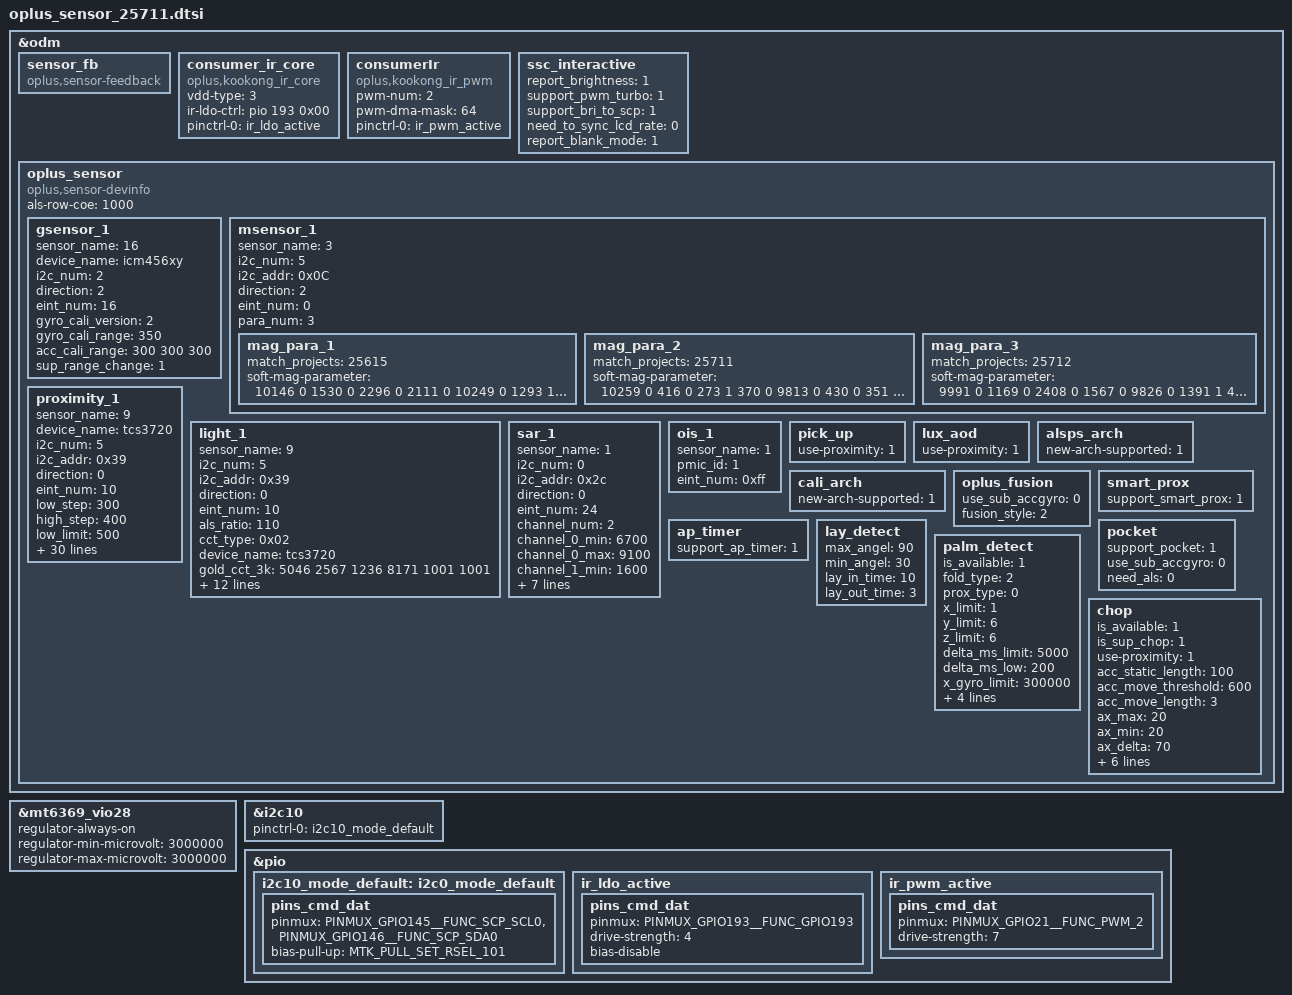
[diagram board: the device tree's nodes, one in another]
&odm {
	sensor_fb: sensor_fb {
		compatible = "oplus,sensor-feedback";
	};
	consumer_ir_core: consumer_ir_core {
		compatible = "oplus,kookong_ir_core";
		status = "okay";
		vdd-type = <3>;  /*0: internal LDO , 1: external LDO , 2: NO VDD  , 3:  GPIO VDD */
		ir-ldo-ctrl = <&pio 193 0x00>;
		pinctrl-names = "default";
		pinctrl-0 = <&ir_ldo_active>;
	};
	consumerIr: consumerIr {
		compatible = "oplus,kookong_ir_pwm";
		status = "okay";
		pwm-num = <2>;
		pwm-dma-mask = <64>;
		pinctrl-names = "default";
		pinctrl-0 = <&ir_pwm_active>;
	};
	ssc_interactive: ssc_interactive {
		report_brightness = <1>;
		support_pwm_turbo = <1>;
		support_bri_to_scp = <1>;
		need_to_sync_lcd_rate = <0>;
		report_blank_mode = <1>;
	};
	oplus_sensor:oplus_sensor {
		compatible = "oplus,sensor-devinfo";
		als-row-coe = <1000>;
		/* sensor start */
		/*
		enum {
			LIS3DH,
			LSM6DS3,
			BMI160,
			LIS2HH12,
			LSM6DSM,
			BMI2XY,
			LSM6DSO,
			ICM4X6XX,
			ICM4263X,
			ICM4N607,
			BMI22X,
			SC7A20,
			MC34X9,
			BMA4XY,
			STK8329,
			BMI3XY,
			ICM456XY,
		};
		*/
		gsensor_1: gsensor_1 {
			status = "okay";
			sensor_name = <16>; // ICM456XY
			device_name = "icm456xy";
			i2c_num = <2>;
			direction = <2>;
			eint_num = <16>;
			gyro_cali_version= <2>;
			gyro_cali_range =<350>;
			acc_cali_range= <300 300 300>;
			sup_range_change = <1>;
		};

		/*
		enum {
			AKM09911,
			MMC3530,
			MMC5603,
			MXG4300,
			AKM09918,
			AKM09919,
		};
		*/
		msensor_1: msensor_1 {
			status = "okay";
			sensor_name = <3>; // MXG4300
			i2c_num = <5>;
			i2c_addr = <0x0C>;
			direction = <2>;
			eint_num = <0>;
			para_num = <3>;
			mag_para_1 {
				match_projects = <25615>;//NFC1
				soft-mag-parameter = <10146 0 1530 0 2296 0 2111 0 10249 0 1293 1 344 1 373 0 10957 0>;
			};
			mag_para_2 {
				match_projects = <25711>;//NO NFC
				soft-mag-parameter = <10259 0 416 0 273 1 370 0 9813 0 430 0 351 1 425 0 11303 0>;
			};
			mag_para_3 {
				match_projects = <25712>;//NFC2
				soft-mag-parameter = <9991 0 1169 0 2408 0 1567 0 9826 0 1391 1 429 1 287 0 11138 0>;
			};
		};
		/*
		enum {
			TMD2725,
			APSD9922,
			STK3335,
			STK3331,
			STK2232,
			TCS3701,
			STK32600,
			STK33502,
			MN78911,
			TCS3720,
			SIP3515,
			STK3329,
			LTR569,
			SIP3510,
			SIP3625,
			STK33C01,
			SIP3535,
			STK63701,
			TMD2765,
			TCS3743,
			SIP3511,
		};
		*/
		proximity_1: proximity_1 {
			status = "okay";
			sensor_name = <9>; // TCS3720
			device_name = "tcs3720";
			i2c_num = <5>;
			i2c_addr = <0x39>;
			direction = <0>;
			eint_num = <10>;
			low_step = <300>;
			high_step = <400>;
			low_limit = <500>;
			high_limit = <570>;
			dirty_low_step = <450>;
			dirty_high_step = <500>;
			ps_dirty_limit = <1800>;
			ps_ir_limit = <500>;
			ps_adjust_min = <0>;
			ps_adjust_max = <800>;
			sampling_count = <5>;
			step_max = <400>;
			step_min = <100>;
			step_div = <2000>;
			anti_shake_delta = <70>;
			dynamic_cali_max = <3000>;
			raw2offset_radio = <1000>;
			offset_max = <15000>;
			offset_range_min = <0>;
			offset_range_max = <65534>;
			force_cali_limit = <3000>;
			cali_jitter_limit = <70>;
			cal_offset_margin = <3000>;
			60hz_psd_us = <11800>;
			90hz_psd_us = <6500>;
			120hz_psd_us = <6500>;
			ps_check_num = <2>;
			ps_mid_filter = <0>;
			dmc_flt_thr = <100>;
			need_to_sync_lcd_rate = <0>;
			sensor-reg = <0xB1 0x0C 0x82 0xE2 0xD9 0xB0 0x1A 0x17>;
			ps_power_config = <12>; // Curved Screen
		};
		light_1: light_1 {
			status = "okay";
			sensor_name = <9>; // TCS3720
			i2c_num = <5>;
			i2c_addr = <0x39>;
			direction = <0>;
			eint_num = <10>;
			als_ratio = <110>;
			cct_type = <0x02>; //0x01 CCT_NORMAL 0x02 CCT_WISE
			device_name = "tcs3720";
			gold_cct_3k = <5046 2567 1236 8171 1001 1001>;
			gold_cct_6k = <3733 2770 1680 7585 1001 1001>;
			sup_changing_rpt = <0>;
			lb_bri_max = <4096>;
			ir_ratio = <10>; // *1000
			als_delay = <390>;
			decision_table_index = <11>;
			available_sensor = <14>;
			gold_cct_factor = <941 946 924 966 1001 1001>;
			high_pwm_cct = <1>;
			als_timer_ms = <100>;
			als_buffer_length = <2>;
			need_gain_cali = <1>;
		};
		/*
		enum {
			SX933x,
			SX937x,
			AW9610X,
		};
		*/
		sar_1: sar_1 {
			status = "okay";
			sensor_name = <1>; // SX937x
			i2c_num = <0>;
			i2c_addr = <0x2c>;
			direction = <0>;
			eint_num = <24>;
			channel_num = <2>;
			channel_0_min = <6700>;
			channel_0_max = <9100>;
			channel_1_min = <1600>;
			channel_1_max = <2300>;
			channel_2_min = <100>;
			channel_2_max = <20000>;
			channel_3_min = <100>;
			channel_3_max = <20000>;
			reg_table_num = <3>;
			sup_move_detect = <1>;
		};

		ois_1: ois_1 {
			status = "okay";
			sensor_name = <1>;
			pmic_id = <1>;
			eint_num = <0xff>;
		};

		pick_up: pick_up {
			status = "okay";
			use-proximity = <1>;
		};
		lux_aod: lux_aod {
			status = "okay";
			use-proximity = <1>;
		};
		alsps_arch: alsps_arch {
			status = "okay";
			new-arch-supported = <1>;
		};
		cali_arch: cali_arch {
			status = "okay";
			new-arch-supported = <1>;
		};
		oplus_fusion: oplus_fusion {
			status = "okay";
			use_sub_accgyro = <0>;
			fusion_style = <2>; // 0:vendor fusion; 1:oppo fusion; 2:mix fusion
		};
		smart_prox: smart_prox {
			status = "okay";
			support_smart_prox = <1>;
		};
		ap_timer: ap_timer {
			status = "okay";
			support_ap_timer = <1>;
		};
		pocket: pocket {
			status = "okay";
			support_pocket = <1>;
			use_sub_accgyro = <0>;
			need_als = <0>;
		};
		lay_detect: lay_detect{
			status = "okay";
			max_angel = <90>;
			min_angel = <30>;
			lay_in_time = <10>;
			lay_out_time = <3>;
		};
		palm_detect: palm_detect{
			status = "okay";
			is_available = <1>;
			fold_type = <2>;
			prox_type = <0>;
			x_limit = <1>;
			y_limit = <6>;
			z_limit = <6>;
			delta_ms_limit = <5000>;
			delta_ms_low = <200>;
			x_gyro_limit = <300000>;
			y_gyro_limit = <300000>;
			z_gyro_limit = <300000>;
			move_limit = <8>;
			als_limit = <3>;
		};
		chop: chop {
			status = "okay";
			is_available = <1>;
			is_sup_chop = <1>;
			use-proximity = <1>;

			acc_static_length = <100>;
			acc_move_threshold = <600>;
			acc_move_length = <3>;
			ax_max = <20>;
			ax_min = <20>;
			ax_delta = <70>;
			ax_peek_cnt = <1>;
			ax_extra_cnt = <2>;
			chop_cnt = <2>;
			chop_between_ms = <250>;
			chop_timeout_ms = <700>;
			chop_buffer_size = <10>;
		};
	};
/* sensor end */
};

/* ps led */
&mt6369_vio28 {
	regulator-always-on;
        regulator-min-microvolt = <3000000>;
        regulator-max-microvolt = <3000000>;
};

/* sar start */
&i2c10 {
	pinctrl-names = "default";
	pinctrl-0 = <&i2c10_mode_default>;
};

&pio {
	i2c10_mode_default: i2c0_mode_default {
		pins_cmd_dat {
			pinmux = <PINMUX_GPIO145__FUNC_SCP_SCL0>,
					<PINMUX_GPIO146__FUNC_SCP_SDA0>;
			/* 0x0:75k 0x1:3k 0x2:5k 0x3:1.5k */
			/* 0x4:10k 0x5:2k 0x6:4k 0x7:1k */
			bias-pull-up = <MTK_PULL_SET_RSEL_101>;
		};
	};
	ir_ldo_active: ir_ldo_active {
		pins_cmd_dat {
			pinmux = <PINMUX_GPIO193__FUNC_GPIO193>;
			drive-strength = <4>;
			bias-disable;
		};
	};
	ir_pwm_active: ir_pwm_active{
		pins_cmd_dat {
			pinmux = <PINMUX_GPIO21__FUNC_PWM_2>;
			drive-strength = <7>;
		};
	};
};
/* sar end */
